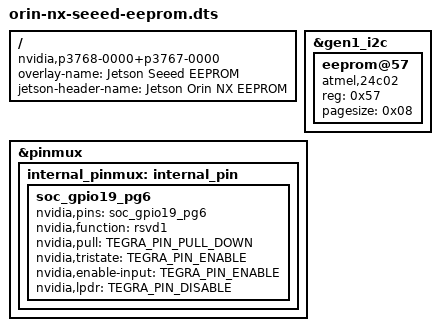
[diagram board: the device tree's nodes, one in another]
/*
 * Copyright (C) 2022 Seeed Studio
 *
 * MIT License
 *
 */

/dts-v1/;
/plugin/;

#include <dt-bindings/pinctrl/pinctrl-tegra.h>

/ {
    overlay-name = "Jetson Seeed EEPROM";
	jetson-header-name = "Jetson Orin NX EEPROM";
	compatible = "nvidia,p3768-0000+p3767-0000", "nvidia,p3509-0000+p3767-0000";

    fragment@0 {
		target = <&gen1_i2c>;

		__overlay__ {
            #address-cells = <1>;
		    #size-cells = <0>;

			eeprom@57 {
                compatible = "atmel,24c02";
                reg = <0x57>;
                pagesize = <0x08>;
            };
		};
	};

	fragment@1 {
        target = <&pinmux>;

        __overlay__ {

            internal_pinmux: internal_pin {

                soc_gpio19_pg6 {
                    nvidia,pins = "soc_gpio19_pg6";
                    nvidia,function = "rsvd1";
                    nvidia,pull = <TEGRA_PIN_PULL_DOWN>;
                    nvidia,tristate = <TEGRA_PIN_ENABLE>;
                    nvidia,enable-input = <TEGRA_PIN_ENABLE>;
                    nvidia,lpdr = <TEGRA_PIN_DISABLE>;
                };
            };
        };
    };
	
};

